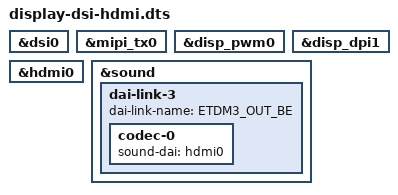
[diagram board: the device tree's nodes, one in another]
/dts-v1/;
/plugin/;

#include <dt-bindings/pinctrl/mt8195-pinfunc.h>

/ {
	fragment@0 {
		target = <&dsi0>;
		__overlay__ {
			status = "okay";
		};
	};

	fragment@1 {
		target = <&mipi_tx0>;
		__overlay__ {
			status = "okay";
		};
	};

	fragment@2 {
		target = <&disp_pwm0>;
		__overlay__ {
			status = "okay";
		};
	};

	fragment@3 {
		target = <&disp_dpi1>;
		__overlay__ {
			status = "okay";
		};
	};

	fragment@4 {
		target = <&hdmi0>;
		__overlay__ {
			status = "okay";
		};
	};

	fragment@5 {
		target = <&sound>;
		__overlay__ {
			dai-link-3 {
				dai-link-name = "ETDM3_OUT_BE";

				codec-0 {
					sound-dai = <&hdmi0>;
				};
			};
		};
	};
};
